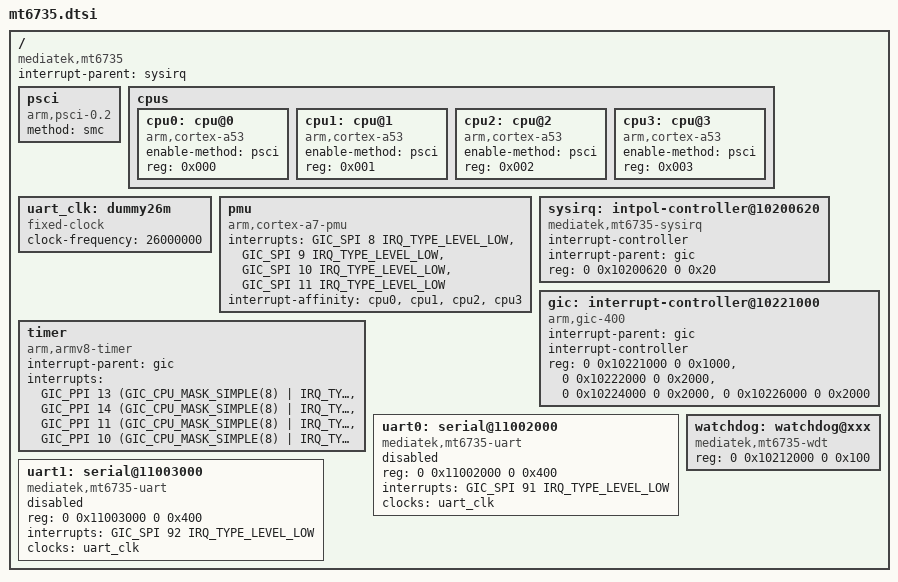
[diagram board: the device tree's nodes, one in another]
// SPDX-License-Identifier: GPL-2.0-or-later
/*
 *Author: Maxim Kutnij <gtk3@inbox.ru>
 */

#include <dt-bindings/interrupt-controller/irq.h>
#include <dt-bindings/interrupt-controller/arm-gic.h>

/ {
	compatible = "mediatek,mt6735";
	interrupt-parent = <&sysirq>;
	#address-cells = <2>;
	#size-cells = <2>;

	psci {
		compatible = "arm,psci-0.2";
		method = "smc";
	};

	cpus {
		#address-cells = <1>;
		#size-cells = <0>;

		cpu0: cpu@0 {
			device_type = "cpu";
			compatible = "arm,cortex-a53";
			enable-method = "psci";
			reg = <0x000>;
		};

		cpu1: cpu@1 {
			device_type = "cpu";
			compatible = "arm,cortex-a53";
			enable-method = "psci";
			reg = <0x001>;
		};

		cpu2: cpu@2 {
			device_type = "cpu";
			compatible = "arm,cortex-a53";
			enable-method = "psci";
			reg = <0x002>;
		};

		cpu3: cpu@3 {
			device_type = "cpu";
			compatible = "arm,cortex-a53";
			enable-method = "psci";
			reg = <0x003>;
		};

	};

	uart_clk: dummy26m {
		compatible = "fixed-clock";
		clock-frequency = <26000000>;
		#clock-cells = <0>;
	};

	pmu {
			compatible = "arm,cortex-a7-pmu";
			interrupts = <GIC_SPI 8 IRQ_TYPE_LEVEL_LOW>,
				<GIC_SPI 9 IRQ_TYPE_LEVEL_LOW>,
				<GIC_SPI 10 IRQ_TYPE_LEVEL_LOW>,
				<GIC_SPI 11 IRQ_TYPE_LEVEL_LOW>;
			interrupt-affinity = <&cpu0>,
					     <&cpu1>,
					     <&cpu2>,
					     <&cpu3>;
	};

	timer {
		compatible = "arm,armv8-timer";
		interrupt-parent = <&gic>;
		interrupts = <GIC_PPI 13
			     (GIC_CPU_MASK_SIMPLE(8) | IRQ_TYPE_LEVEL_LOW)>,
			     <GIC_PPI 14
			     (GIC_CPU_MASK_SIMPLE(8) | IRQ_TYPE_LEVEL_LOW)>,
			     <GIC_PPI 11
			     (GIC_CPU_MASK_SIMPLE(8) | IRQ_TYPE_LEVEL_LOW)>,
			     <GIC_PPI 10
			     (GIC_CPU_MASK_SIMPLE(8) | IRQ_TYPE_LEVEL_LOW)>;
	};

	sysirq: intpol-controller@10200620 {
		compatible = "mediatek,mt6735-sysirq",
			     "mediatek,mt6577-sysirq";
		interrupt-controller;
		#interrupt-cells = <3>;
		interrupt-parent = <&gic>;
		reg = <0 0x10200620 0 0x20>;
	};

	gic: interrupt-controller@10221000 {
		compatible = "arm,gic-400";
		#interrupt-cells = <3>;
		interrupt-parent = <&gic>;
		interrupt-controller;
		reg = <0 0x10221000 0 0x1000>,
		      <0 0x10222000 0 0x2000>,
		      <0 0x10224000 0 0x2000>,
		      <0 0x10226000 0 0x2000>;
	};

	uart0: serial@11002000 {
		compatible = "mediatek,mt6735-uart",
			     "mediatek,mt6577-uart";
		reg = <0 0x11002000 0 0x400>;
		interrupts = <GIC_SPI 91 IRQ_TYPE_LEVEL_LOW>;
		clocks = <&uart_clk>;
		status = "disabled";
	};

	uart1: serial@11003000 {
		compatible = "mediatek,mt6735-uart",
			     "mediatek,mt6577-uart";
		reg = <0 0x11003000 0 0x400>;
		interrupts = <GIC_SPI 92 IRQ_TYPE_LEVEL_LOW>;
		clocks = <&uart_clk>;
		status = "disabled";
	};

	watchdog: watchdog@xxx {
		compatible = "mediatek,mt6735-wdt", "mediatek,mt6589-wdt";
		reg = <0 0x10212000 0 0x100>;
	};
};
